# ATmega169PA register map
Vendor: Atmel; File version: 1.0
CPU: other r0p0, little endian, no MPU, no FPU, 4 interrupt priority bits
Registers are 8-bit, read-write, reset 0x0 unless marked. A register's access mark holds for its fields unless they carry their own. Offsets are from the block's base; [hi:lo] are bit positions.

## TC1 — Timer/Counter, 16-bit
Base 0x00800036
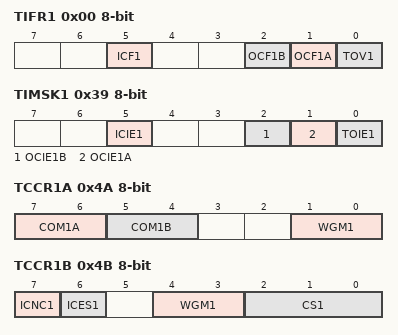
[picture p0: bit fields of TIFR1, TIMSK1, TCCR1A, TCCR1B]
0x00 TIFR1 — Timer/Counter1 Interrupt Flag register (read-only for debugger)
  [5] ICF1 — Input Capture Flag 1
  [2] OCF1B — Output Compare Flag 1B
  [1] OCF1A — Output Compare Flag 1A
  [0] TOV1 — Timer/Counter1 Overflow Flag
0x39 TIMSK1 — Timer/Counter1 Interrupt Mask Register
  [5] ICIE1 — Timer/Counter1 Input Capture Interrupt Enable
  [2] OCIE1B — Timer/Counter1 Output Compare B Match Interrupt Enable
  [1] OCIE1A — Timer/Counter1 Output Compare A Match Interrupt Enable
  [0] TOIE1 — Timer/Counter1 Overflow Interrupt Enable
0x4A TCCR1A — Timer/Counter1 Control Register A
  [7:6] COM1A — Compare Output Mode 1A, bits
  [5:4] COM1B — Compare Output Mode 1B, bits
  [1:0] WGM1 — Waveform Generation Mode
0x4B TCCR1B — Timer/Counter1 Control Register B
  [7] ICNC1 — Input Capture 1 Noise Canceler
  [6] ICES1 — Input Capture 1 Edge Select
  [4:3] WGM1 — Waveform Generation Mode
  [2:0] CS1 — Prescaler source of Timer/Counter 1
    0=NO_CLOCK_SOURCE_STOPPED; 1=RUNNING_NO_PRESCALING; 2=RUNNING_CLK_8; 3=RUNNING_CLK_64; 4=RUNNING_CLK_256; 5=RUNNING_CLK_1024; 6=RUNNING_EXTCLK_TN_FALLING_EDGE; 7=RUNNING_EXTCLK_TN_RISING_EDGE
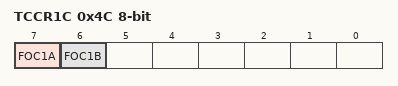
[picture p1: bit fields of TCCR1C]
0x4C TCCR1C — Timer/Counter 1 Control Register C
  [7] FOC1A — Force Output Compare 1A
  [6] FOC1B — Force Output Compare 1B
0x4E TCNT1 16-bit (reset mask 0xFF) — Timer/Counter1 Bytes
  [15:0] TCNT1 — Timer/Counter1 bits
0x50 ICR1 16-bit (reset mask 0xFF) — Timer/Counter1 Input Capture Register Bytes
  [15:0] ICR1 — Timer/Counter1 Input Capture
0x52 OCR1A 16-bit (reset mask 0xFF) — Timer/Counter1 Output Compare Register A Bytes
  [15:0] OCR1A — Timer/Counter1 Output Compare A
0x54 OCR1B 16-bit (reset mask 0xFF) — Timer/Counter1 Output Compare Register B Bytes
  [15:0] OCR1B — Timer/Counter1 Output Compare B

## TC2 — Timer/Counter, 8-bit Async
Base 0x00800037
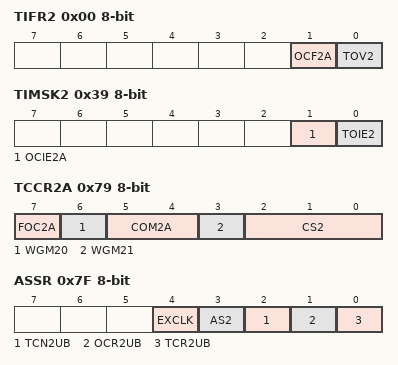
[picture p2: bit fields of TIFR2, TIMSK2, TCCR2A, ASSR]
0x00 TIFR2 — Timer/Counter2 Interrupt Flag Register (read-only for debugger)
  [1] OCF2A — Timer/Counter2 Output Compare Flag 2
  [0] TOV2 — Timer/Counter2 Overflow Flag
0x0C GTCCR — General Timer/Counter Control Register
  [1] PSR2 — Prescaler Reset Timer/Counter2
0x39 TIMSK2 — Timer/Counter2 Interrupt Mask register
  [1] OCIE2A — Timer/Counter2 Output Compare Match Interrupt Enable
  [0] TOIE2 — Timer/Counter2 Overflow Interrupt Enable
0x79 TCCR2A — Timer/Counter2 Control Register
  [7] FOC2A — Force Output Compare A
  [6] WGM20 — Waveform Generation Mode
    0=NORMAL; 1=CTC
  [5:4] COM2A — Compare Output Mode bits
  [3] WGM21 — Waveform Generation Mode
  [2:0] CS2 — Clock Select bits
    0=NO_CLOCK_SOURCE_STOPPED; 1=RUNNING_NO_PRESCALING; 2=RUNNING_CLK_8; 3=RUNNING_CLK_32; 4=RUNNING_CLK_64; 5=RUNNING_CLK_128; 6=RUNNING_CLK_256; 7=RUNNING_CLK_1024
0x7B TCNT2 — Timer/Counter2
  [7:0] TCNT2 — Timer/Counter2 bits
0x7C OCR2A — Timer/Counter2 Output Compare Register
  [7:0] OCR2A — Timer/Counter2 Output Compare A
0x7F ASSR — Asynchronous Status Register
  [4] EXCLK — Enable External Clock Interrupt
  [3] AS2 — AS2: Asynchronous Timer/Counter2
  [2] TCN2UB — TCN2UB: Timer/Counter2 Update Busy
  [1] OCR2UB — Output Compare Register2 Update Busy
  [0] TCR2UB — TCR2UB: Timer/Counter Control Register2 Update Busy

## USART0 — USART
Base 0x008000C0
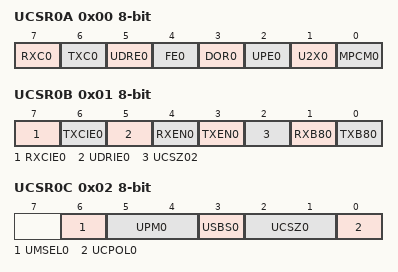
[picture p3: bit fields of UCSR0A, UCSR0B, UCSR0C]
0x00 UCSR0A — USART Control and Status Register A (read-only for debugger)
  [7] RXC0 ro — USART Receive Complete
  [6] TXC0 — USART Transmit Complete
  [5] UDRE0 ro — USART Data Register Empty
  [4] FE0 ro — Framing Error
  [3] DOR0 ro — Data overRun
  [2] UPE0 ro — USART Parity Error
  [1] U2X0 — Double the USART Transmission Speed
  [0] MPCM0 — Multi-processor Communication Mode
0x01 UCSR0B — USART Control and Status Register B
  [7] RXCIE0 — RX Complete Interrupt Enable
  [6] TXCIE0 — TX Complete Interrupt Enable
  [5] UDRIE0 — USART Data Register Empty Interrupt Enable
  [4] RXEN0 — Receiver Enable
  [3] TXEN0 — Transmitter Enable
  [2] UCSZ02 — Character Size
  [1] RXB80 — Receive Data Bit 8
  [0] TXB80 — Transmit Data Bit 8
0x02 UCSR0C — USART Control and Status Register C
  [6] UMSEL0 — USART Mode Select
    0=ASYNCHRONOUS_OPERATION; 1=SYNCHRONOUS_OPERATION
  [5:4] UPM0 — Parity Mode Bits
    0=DISABLED; 2=ENABLED_EVEN_PARITY; 3=ENABLED_ODD_PARITY
  [3] USBS0 — Stop Bit Select
    0=1_BIT; 1=2_BIT
  [2:1] UCSZ0 — Character Size
  [0] UCPOL0 — Clock Polarity
0x04 UBRR0 16-bit (reset mask 0xFF) — USART Baud Rate Register Bytes
  [11:0] UBRR0 — USART Baud Rate bits
0x06 UDR0 — USART I/O Data Register (write-only for debugger)
  [7:0] UDR0 — USART I/O Data bits

## USI — Universal Serial Interface
Base 0x008000B8
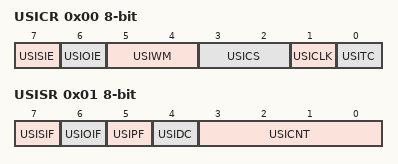
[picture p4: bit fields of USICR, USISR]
0x00 USICR — USI Control Register
  [7] USISIE — Start Condition Interrupt Enable
  [6] USIOIE — Counter Overflow Interrupt Enable
  [5:4] USIWM — USI Wire Mode Bits
    0=NORMAL_OPERATION; 1=THREE_WIRE_MODE; 2=TWO_WIRE_MODE; 3=TWO_WIRE_MODE_HELD_LOW
  [3:2] USICS — USI Clock Source Select Bits
  [1] USICLK — Clock Strobe
  [0] USITC — Toggle Clock Port Pin
0x01 USISR — USI Status Register (read-only for debugger)
  [7] USISIF — Start Condition Interrupt Flag
  [6] USIOIF — Counter Overflow Interrupt Flag
  [5] USIPF — Stop Condition Flag
  [4] USIDC — Data Output Collision
  [3:0] USICNT — USI Counter Value Bits
0x02 USIDR — USI Data Register
  [7:0] USIDR — USI Data bits

## WDT — Watchdog Timer
Base 0x00800060
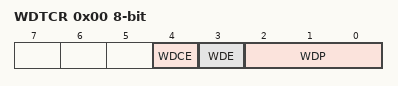
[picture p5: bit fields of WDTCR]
0x00 WDTCR — Watchdog Timer Control Register
  [4] WDCE — Watchdog Change Enable
  [3] WDE — Watch Dog Enable
  [2:0] WDP — Watch Dog Timer Prescaler bits
    0=OSCILLATOR_CYCLES_16K; 1=OSCILLATOR_CYCLES_32K; 2=OSCILLATOR_CYCLES_64K; 3=OSCILLATOR_CYCLES_128K; 4=OSCILLATOR_CYCLES_256K; 5=OSCILLATOR_CYCLES_512K; 6=OSCILLATOR_CYCLES_1024K; 7=OSCILLATOR_CYCLES_2048K
